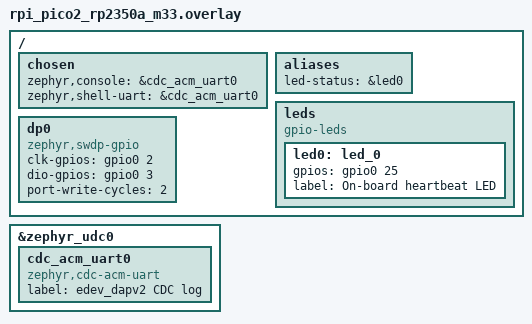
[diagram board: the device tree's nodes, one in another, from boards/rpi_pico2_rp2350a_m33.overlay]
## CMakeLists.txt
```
# SPDX-License-Identifier: Apache-2.0
#
# edev_dapv2 — Zephyr RTOS port.
#
# CMSIS-DAP v2 debug probe firmware for Raspberry Pi Pico 2 (RP2350).
# Ports the working pico-sdk implementation at firmware/projects/edev_dapv2/ to
# Zephyr 4.4.x. The SWD bit-banger is PIO-driven (probe_swd.pio); the rest of
# the stack uses Zephyr USB-Device-Next + subsys/dap.

cmake_minimum_required(VERSION 3.20.0)

find_package(Zephyr REQUIRED HINTS $ENV{ZEPHYR_BASE})
project(edev_dapv2_zephyr LANGUAGES C)

# Pull in the sample USBD helper (sample_usbd_setup_device + Kconfig symbols).
# common.cmake adds sample_usbd_init.c when CONFIG_USB_DEVICE_STACK_NEXT=y and
# wires the include directory.
include(${ZEPHYR_BASE}/samples/subsys/usb/common/common.cmake)

# --------------------------------------------------------------------------
# pioasm — autogenerate probe_swd.pio.h from the .pio source at configure
# time. The pico-sdk vendors pioasm; we use whichever we can find in this
# order: (1) PIOASM env var, (2) system pioasm on PATH, (3) the pico-sdk
# install at ~/.pico-sdk/tools/2.2.0/pioasm/pioasm. If none works, fall back
# to the header that is checked into pio/ so a build is still possible on a
# machine without pioasm.
# --------------------------------------------------------------------------
set(PIO_SRC ${CMAKE_CURRENT_SOURCE_DIR}/pio/probe_swd.pio)
set(PIO_HDR ${CMAKE_CURRENT_BINARY_DIR}/zephyr/include/generated/probe_swd.pio.h)

find_program(PIOASM_EXECUTABLE
    NAMES pioasm
    HINTS
        $ENV{PIOASM}
        $ENV{PICO_SDK_PATH}/tools/pioasm
        $ENV{HOME}/.pico-sdk/tools/2.2.0/pioasm
        $ENV{HOME}/.pico-sdk/tools/2.1.1/pioasm
    DOC "Path to the pioasm executable from pico-sdk"
)

if(PIOASM_EXECUTABLE)
    message(STATUS "pioasm: ${PIOASM_EXECUTABLE} (regenerate ${PIO_HDR} from .pio source)")
    add_custom_command(
        OUTPUT ${PIO_HDR}
        COMMAND ${CMAKE_COMMAND} -E make_directory ${CMAKE_CURRENT_BINARY_DIR}/zephyr/include/generated
        COMMAND ${PIOASM_EXECUTABLE} -o c-sdk ${PIO_SRC} ${PIO_HDR}
        DEPENDS ${PIO_SRC}
        COMMENT "pioasm: ${PIO_SRC} -> probe_swd.pio.h"
        VERBATIM
    )
    add_custom_target(probe_swd_pio_header DEPENDS ${PIO_HDR})
    add_dependencies(app probe_swd_pio_header)
    set(PIO_INCLUDE_DIR ${CMAKE_CURRENT_BINARY_DIR}/zephyr/include/generated)
else()
    message(WARNING
        "pioasm not found — falling back to checked-in pio/probe_swd.pio.h. "
        "Edits to probe_swd.pio will NOT be picked up automatically. "
        "Set PIOASM env var or install pico-sdk to enable regeneration.")
    set(PIO_INCLUDE_DIR ${CMAKE_CURRENT_SOURCE_DIR}/pio)
endif()

target_sources(app PRIVATE
    src/main.c
    src/swclk_keepalive.c
    drivers/dp/swdp_pio_rpi_pico.c
)

# nRF5340 ops — recover/erase/write/read primitives. Off by default;
# enable with CONFIG_EDEV_NRF53_OPS=y. Algorithm reference:
# docs/NRF5340_ALGORITHMS.md.
target_sources(app PRIVATE
    $<$<BOOL:${CONFIG_EDEV_NRF53_OPS}>:src/nrf53/nrf53_dp.c>
    $<$<BOOL:${CONFIG_EDEV_NRF53_OPS}>:src/nrf53/nrf53_ap.c>
    $<$<BOOL:${CONFIG_EDEV_NRF53_OPS}>:src/nrf53/nrf53_ctrl_ap.c>
    $<$<BOOL:${CONFIG_EDEV_NRF53_OPS}>:src/nrf53/nrf53_nvmc.c>
    $<$<BOOL:${CONFIG_EDEV_NRF53_OPS}>:src/nrf53/nrf53_uicr.c>
    $<$<BOOL:${CONFIG_EDEV_NRF53_OPS}>:src/nrf53/nrf53_stubs.c>
    $<$<BOOL:${CONFIG_EDEV_NRF53_OPS}>:src/nrf53/nrf53_recover.c>
    $<$<BOOL:${CONFIG_EDEV_NRF53_OPS}>:src/nrf53/nrf53_read_mem.c>
    $<$<BOOL:${CONFIG_EDEV_NRF53_OPS}>:src/nrf53/nrf53_flash_write.c>
    $<$<BOOL:${CONFIG_EDEV_NRF53_OPS}>:src/nrf53/nrf53_target_info.c>
    $<$<BOOL:${CONFIG_EDEV_NRF53_OPS}>:src/nrf53/nrf53_vendor.c>
)

target_include_directories(app PRIVATE
    src
    src/nrf53
    ${PIO_INCLUDE_DIR}
)
```

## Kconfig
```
# SPDX-License-Identifier: Apache-2.0
#
# edev_dapv2 Zephyr port — application Kconfig.
#
# We reuse the sample USBD helper from samples/subsys/usb/common/. The Zephyr
# upstream policy is that the SAMPLE_USBD_* symbols are sample-scope only — for
# the long-term port we should mint our own EDEV_USBD_* symbols and helper. For
# the M1 scaffold we follow the same shortcut the upstream DAP sample uses.

source "samples/subsys/usb/common/Kconfig.sample_usbd"

rsource "src/nrf53/Kconfig.nrf53"

source "Kconfig.zephyr"
```

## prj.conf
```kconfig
# SPDX-License-Identifier: Apache-2.0
#
# edev_dapv2 Zephyr port — milestone 1 config.
#
# Goal of M1: boot on Pico 2, expose a USB CDC ACM console, blink the on-board
# LED. No DAP wiring yet. Once this builds + flashes + enumerates, layer on the
# DAP subsystem and the swdp_pio_rpi_pico driver.

# Kernel
CONFIG_MAIN_STACK_SIZE=2048
CONFIG_HEAP_MEM_POOL_SIZE=4096

# Console + logging — routed to USB CDC ACM via board overlay
CONFIG_CONSOLE=y
CONFIG_UART_CONSOLE=y
CONFIG_SERIAL=y
CONFIG_UART_INTERRUPT_DRIVEN=y
CONFIG_UART_LINE_CTRL=y
CONFIG_STDOUT_CONSOLE=y

CONFIG_LOG=y
CONFIG_LOG_DEFAULT_LEVEL=3
CONFIG_LOG_MODE_DEFERRED=y

# USB-Device-Next stack
CONFIG_USB_DEVICE_STACK_NEXT=y
CONFIG_USBD_CDC_ACM_LOG_LEVEL_OFF=y
CONFIG_CDC_ACM_SERIAL_INITIALIZE_AT_BOOT=n

# Sample USBD helper (we reuse samples/subsys/usb/common/sample_usbd_init.c)
# VID 0x2E8A is Raspberry Pi Trading's; PID 0x000C is the same value used by
# the pico-sdk edev_dapv2 firmware so host-side allowlists keep working.
CONFIG_SAMPLE_USBD_VID=0x2E8A
CONFIG_SAMPLE_USBD_PID=0x000C
CONFIG_SAMPLE_USBD_MANUFACTURER="Edevkit"
CONFIG_SAMPLE_USBD_PRODUCT="edev_dapv2 (Zephyr)"
CONFIG_SAMPLE_USBD_SELF_POWERED=n
CONFIG_SAMPLE_USBD_REMOTE_WAKEUP=n
CONFIG_SAMPLE_USBD_20_EXTENSION_DESC=y

# Chip-ID serial number — Zephyr's USBD framework calls hwinfo to pull
# RP2350's 64-bit unique ID and exposes it as the SerialNumber string
# descriptor when CONFIG_HWINFO is enabled. Format is a hex string (not the
# "EDV-XXXX-XXXX-XXXX-XXXX" used by pico-sdk firmware — cosmetic only).
CONFIG_HWINFO=y

# BOS chain — needed for MS OS 2.0 Platform Capability descriptor (lets
# Windows auto-bind WINUSB without a .inf file).
CONFIG_USBD_BOS_SUPPORT=y

# Identity strings exposed via DAP_Info command (CMSIS-DAP request 0x00).
CONFIG_CMSIS_DAP_PROBE_VENDOR="Edevkit"
CONFIG_CMSIS_DAP_PROBE_NAME="edev_dapv2 CMSIS-DAP"
CONFIG_CMSIS_DAP_DEVICE_VENDOR="Edevkit"
CONFIG_CMSIS_DAP_DEVICE_NAME="edev_dapv2 (Zephyr)"

# GPIO + drivers
CONFIG_GPIO=y

# DAP subsystem — upstream Zephyr cmsis_dap.c with the SWDP bit-banger as M2
# placeholder. The PIO-backed swdp_pio_rpi_pico driver replaces the bit-banger
# in M3 (DT swap from zephyr,swdp-gpio to zephyr,swdp-pio-rpi-pico).
CONFIG_DAP=y
CONFIG_DAP_BACKEND_USB=y
CONFIG_DAP_LOG_LEVEL_INF=y
CONFIG_DP_DRIVER_LOG_LEVEL_INF=y

# edevkit nRF5340 ops — exposed as CMSIS-DAP vendor commands 0x84..0x8B.
# Algorithm reference: docs/NRF5340_ALGORITHMS.md. Each step in the build
# checklist (§9) wires in one more vendor command; today (step 2) only
# 0x85 NRF53_ERASE is active. Requires the weak-vendor-cmd patch at
# zephyr-patches/0003-cmsis_dap-weak-vendor-cmd-handler.patch.
CONFIG_EDEV_NRF53_OPS=y
CONFIG_EDEV_NRF53_OPS_LOG_LEVEL_INF=y
```

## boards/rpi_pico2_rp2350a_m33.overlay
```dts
/*
 * SPDX-License-Identifier: Apache-2.0
 *
 * edev_dapv2 (Zephyr port) — board overlay for Raspberry Pi Pico 2 (RP2350A,
 * Cortex-M33 cores).
 *
 * Wires:
 *   - USB CDC ACM as the Zephyr console (replaces UART0 console default)
 *   - LED alias to the on-board GPIO25 LED (heartbeat)
 *   - Reserves SWD pins (GPIO2/3) and JTAG pins (GPIO4/5) for later milestones;
 *     no driver is attached yet — driver bindings land with the swdp_pio_rpi
 *     driver in M4.
 */

/ {
	chosen {
		zephyr,console = &cdc_acm_uart0;
		zephyr,shell-uart = &cdc_acm_uart0;
	};

	aliases {
		led-status = &led0;
	};

	leds {
		compatible = "gpio-leds";
		led0: led_0 {
			gpios = <&gpio0 25 GPIO_ACTIVE_HIGH>;
			label = "On-board heartbeat LED";
		};
	};

};

/*
 * SWD Debug Port — production: upstream Zephyr GPIO bit-banger.
 *
 * The PIO-driven driver (raspberrypi,pico-swdp-pio) is preserved in the
 * tree (drivers/dp/) but its DT node is disabled. The GPIO bit-banger
 * proves out the rest of the stack (USB, DAP dispatcher, identity, BLE
 * roadmap, etc.) at the cost of slower SWD speed (~few MHz vs PIO's
 * 25 MHz target). Wire-level FAULT in the PIO driver still needs a
 * logic-analyser session to crack — see UPSTREAM_VALIDATES.md.
 *
 * Pin assignments match probe_pins.h in the pico-sdk project: SWCLK=GP2,
 * SWDIO=GP3 (with internal pull-up — Zephyr's GPIO driver handles RP2350
 * pad isolation correctly via gpio_pin_configure_dt).
 */
/ {
	dp0: dp0 {
		compatible = "zephyr,swdp-gpio";
		status = "okay";
		clk-gpios = <&gpio0 2 GPIO_ACTIVE_HIGH>;
		dio-gpios = <&gpio0 3 GPIO_PULL_UP>;
		port-write-cycles = <2>;
	};
};

&zephyr_udc0 {
	cdc_acm_uart0: cdc_acm_uart0 {
		compatible = "zephyr,cdc-acm-uart";
		label = "edev_dapv2 CDC log";
	};
};
```

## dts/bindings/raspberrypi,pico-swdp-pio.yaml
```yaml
# SPDX-License-Identifier: Apache-2.0
#
# PIO-driven SWDP (Serial Wire Debug Port) for RP2040 / RP2350.
#
# Drop-in replacement for the upstream zephyr,swdp-gpio binding when speed
# matters — the PIO state machine clocks SWD up to 25 MHz (vs ~few-MHz for
# the GPIO bit-banger). The PIO program is the same one the pico-sdk
# implementation at firmware/projects/edev_dapv2/src/pio/probe_swd.pio uses.
#
# Example:
#
#   &pio1 {
#       status = "okay";
#       dp0: dp0 {
#           compatible = "raspberrypi,pico-swdp-pio";
#           status = "okay";
#           clk-gpios = <&gpio0 2 GPIO_ACTIVE_HIGH>;     /* SWCLK */
#           dio-gpios = <&gpio0 3 GPIO_PULL_UP>;         /* SWDIO */
#           reset-gpios = <&gpio0 6 GPIO_ACTIVE_LOW>;    /* nRESET (optional) */
#       };
#   };

description: |
  Raspberry Pi Pico PIO-driven SWDP driver. Implements zephyr/drivers/swdp.h
  for use with subsys/dap. The parent node must be a raspberrypi,pico-pio
  controller; the driver allocates one state machine on it.

compatible: "raspberrypi,pico-swdp-pio"

include: base.yaml

properties:
  clk-gpios:
    type: phandle-array
    required: true
    description: SWCLK pin (always driven by the PIO state machine).

  dio-gpios:
    type: phandle-array
    required: true
    description: SWDIO pin (bidirectional; direction managed by PIO).

  reset-gpios:
    type: phandle-array
    description: |
      Optional nRESET line to the target. Driven open-drain — low pulls the
      target into reset, high (input/Hi-Z) releases it.

  port-write-cycles:
    type: int
    default: 2
    description: |
      Compatibility knob carried over from zephyr,swdp-gpio. Unused by the
      PIO driver because PIO clocks have deterministic phase; kept so
      existing overlays migrate cleanly.
```

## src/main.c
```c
/*
 * SPDX-License-Identifier: Apache-2.0
 *
 * edev_dapv2 (Zephyr port) — M1 entry point.
 *
 * Goal: bring up the board on Zephyr, prove USB CDC console + LED heartbeat
 * work end-to-end before any DAP code lands. Mirrors src/main.c in the pico-sdk
 * project (firmware/projects/edev_dapv2/src/main.c) — same boot order, same
 * banner content, same heartbeat cadence — so a side-by-side comparison while
 * porting is straightforward.
 */

/* Order matters: kernel.h must precede dap_link.h — the latter uses atomic_t
 * without including <zephyr/sys/atomic.h> itself (upstream header omission). */
#include <zephyr/kernel.h>

#include <zephyr/dap/dap_link.h>
#include <zephyr/device.h>
#include <zephyr/drivers/gpio.h>
#include <zephyr/drivers/uart.h>
#include <zephyr/logging/log.h>
#include <zephyr/sys/byteorder.h>
#include <zephyr/usb/bos.h>
#include <zephyr/usb/msos_desc.h>
#include <zephyr/usb/usbd.h>

#include <sample_usbd.h>

#include <pico/bootrom.h>

#if defined(CONFIG_EDEV_NRF53_OPS)
#include "nrf53/nrf53.h"
#endif

LOG_MODULE_REGISTER(edev_dapv2, LOG_LEVEL_INF);

/* MS OS 2.0 BOS — pulled in *after* LOG_MODULE_REGISTER because the static
 * msosv2_to_host_cb in the header uses LOG_INF. The CMSIS-DAP v2 standard
 * device interface GUID it advertises is what makes Windows auto-bind WINUSB
 * (and what makes probe-rs / pyocd / OpenOCD discover the probe). */
#include "msosv2.h"

/* probe-rs gates CMSIS-DAP v2 discovery on bcdDevice >= 0x0220 — see the
 * memory note reference_probe_rs_bcd_device_gate. The Zephyr USBD default
 * uses Zephyr's kernel version; override at runtime to 0x0220 to satisfy the
 * gate without forking the framework. */
#define EDEV_DAPV2_BCD_DEVICE	0x0220

#define LED_NODE	DT_ALIAS(led_status)
#define HEARTBEAT_MS	1000

static const struct gpio_dt_spec led = GPIO_DT_SPEC_GET_OR(LED_NODE, gpios, {0});

/*
 * DAP Link context bound to the SWDP device declared in the board overlay.
 * The compatible string matches the binding in
 * dts/bindings/raspberrypi,pico-swdp-pio.yaml — the PIO-driven backend
 * preserves the 25 MHz SWD speed of the pico-sdk firmware.
 */
DAP_LINK_CONTEXT_DEFINE(edev_dap_ctx, DEVICE_DT_GET_ONE(zephyr_swdp_gpio));

static int setup_usb(void)
{
	struct usbd_context *ctx = sample_usbd_setup_device(NULL);

	if (ctx == NULL) {
		LOG_ERR("USBD setup failed");
		return -ENODEV;
	}

	int ret = usbd_add_descriptor(ctx, &bos_vreq_msosv2);
	if (ret) {
		LOG_ERR("Failed to add MS OS 2.0 BOS: %d", ret);
		return ret;
	}

	ret = usbd_device_set_bcd_device(ctx, EDEV_DAPV2_BCD_DEVICE);
	if (ret) {
		LOG_WRN("Could not set bcdDevice: %d (probe-rs may not list)",
			ret);
	}

	ret = usbd_init(ctx);
	if (ret) {
		LOG_ERR("usbd_init failed: %d", ret);
		return ret;
	}

	ret = usbd_enable(ctx);
	if (ret) {
		LOG_ERR("usbd_enable failed: %d", ret);
		return ret;
	}

	return 0;
}

static void wait_for_dtr(const struct device *console)
{
	uint32_t dtr = 0;

	while (!dtr) {
		uart_line_ctrl_get(console, UART_LINE_CTRL_DTR, &dtr);
		k_sleep(K_MSEC(100));
	}
}

/*
 * 1200-baud-to-BOOTSEL reboot trick.
 *
 * The pico-sdk firmware ports this via TinyUSB's tud_cdc_line_coding_cb. The
 * Zephyr USB-Device-Next CDC ACM driver doesn't expose a line-coding callback,
 * so we poll the console's baud rate every 250 ms; if the host opens at 1200
 * baud (e.g. `stty -f /dev/cu.usbmodem* 1200`) we hand off to the RP2350
 * bootrom to enter UF2 mass-storage mode. This is the same UX the host-side
 * `picotool` / pico-sdk firmware expects.
 */
#define EDEV_REBOOT_MAGIC_BAUD	1200u

static void bootsel_watch_entry(void *a, void *b, void *c)
{
	ARG_UNUSED(a);
	ARG_UNUSED(b);
	ARG_UNUSED(c);

	const struct device *console = DEVICE_DT_GET(DT_CHOSEN(zephyr_console));

	while (!device_is_ready(console)) {
		k_sleep(K_MSEC(100));
	}

	while (1) {
		uint32_t baud = 0;

		uart_line_ctrl_get(console, UART_LINE_CTRL_BAUD_RATE, &baud);
		if (baud == EDEV_REBOOT_MAGIC_BAUD) {
			LOG_WRN("1200-baud — entering BOOTSEL");
			k_sleep(K_MSEC(50));	/* let the log line drain */
			reset_usb_boot(0, 0);
			/* not reached */
		}
		k_sleep(K_MSEC(250));
	}
}

K_THREAD_DEFINE(bootsel_watch, 1024, bootsel_watch_entry, NULL, NULL, NULL,
		K_LOWEST_APPLICATION_THREAD_PRIO, 0, 1000);

static int setup_dap(void)
{
	int ret = dap_link_init(&edev_dap_ctx);

	if (ret) {
		LOG_ERR("dap_link_init failed: %d", ret);
		return ret;
	}

	ret = dap_link_backend_usb_init(&edev_dap_ctx);
	if (ret) {
		LOG_ERR("dap_link_backend_usb_init failed: %d", ret);
		return ret;
	}

	return 0;
}

int main(void)
{
	int ret;

	if (!gpio_is_ready_dt(&led)) {
		LOG_WRN("Status LED not ready");
	} else {
		gpio_pin_configure_dt(&led, GPIO_OUTPUT_INACTIVE);
	}

	ret = setup_dap();
	if (ret) {
		return ret;
	}

#if defined(CONFIG_EDEV_NRF53_OPS)
	/* Bind the SWDP device our nRF5340 ops use. Same device as the DAP
	 * context — we just need our own handle to it because we call the
	 * driver directly (bypassing the DAP dispatcher) when handling our
	 * custom vendor commands (0x84..0x8B). Safe because dispatching is
	 * single-flight: one DAP packet processes at a time. */
	nrf53_status_t ns = nrf53_bind_swdp(DEVICE_DT_GET_ONE(zephyr_swdp_gpio));
	if (ns != NRF53_OK) {
		LOG_WRN("nrf53 ops disabled — SWDP bind failed: %s",
			nrf53_status_str(ns));
	}
#endif /* CONFIG_EDEV_NRF53_OPS */

	ret = setup_usb();
	if (ret) {
		return ret;
	}

	/*
	 * Wait for the host to open the CDC ACM port before printing the boot
	 * banner — otherwise the first ~hundred ms of log lines vanish into a
	 * not-yet-enumerated endpoint. Same idea as the pico-sdk firmware,
	 * which calls tud_cdc_connected() before logging the banner.
	 */
	const struct device *console = DEVICE_DT_GET(DT_CHOSEN(zephyr_console));
	if (device_is_ready(console)) {
		wait_for_dtr(console);
	}

	LOG_INF("edev_dapv2 (Zephyr port) — boot ok");
	LOG_INF("Built: %s %s", __DATE__, __TIME__);

	/* SWCLK keep-alive is staged but LEFT OFF at boot. Live-fire
	 * testing 2026-06-29 showed that an asynchronous SWCLK pulse train
	 * (5 kHz isolated single-cycle pulses) breaks SWD protocol timing
	 * — the chip's frame aligner counts the keep-alive cycles, so
	 * probe-rs's subsequent DPIDR read lands at the wrong bit offset
	 * and returns Protocol Error.
	 *
	 * The right fix is to insert idle cycles INSIDE Zephyr's
	 * drivers/dp/swdp_bitbang.c sw_transfer (the WAIT-ACK retry path
	 * currently exits without clocking; idle cycles between retries
	 * would keep the debug clock alive in-protocol). That's an
	 * upstream patch — tracked in NRF5340_FIRMWARE_GAP.md and the
	 * memory note nrf5340-edev-vs-jlink-firmware-gap-2026-06-29.
	 *
	 * Leaving the timer scaffolding in place so the next session can
	 * call edev_swclk_keepalive_resume() once the in-protocol path is
	 * built. For now it stays gated off via keepalive_active=0. */

	while (1) {
		if (gpio_is_ready_dt(&led)) {
			gpio_pin_toggle_dt(&led);
		}
		k_sleep(K_MSEC(HEARTBEAT_MS));
	}

	return 0;
}
```

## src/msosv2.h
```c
/*
 * Copyright (c) 2016-2019 Intel Corporation
 * Copyright (c) 2023-2024 Nordic Semiconductor ASA
 *
 * SPDX-License-Identifier: Apache-2.0
 *
 * Adapted for edev_dapv2 (Zephyr port). Keeps the standard CMSIS-DAP v2
 * device interface GUID {CDB3B5AD-293B-4663-AA36-1AAE46463776} so probe-rs
 * / pyocd / OpenOCD recognise the probe through their existing CMSIS-DAP v2
 * discovery paths on Windows.
 */

#ifndef EDEV_DAPV2_MSOSV2_H
#define EDEV_DAPV2_MSOSV2_H

#define SAMPLE_MSOS2_VENDOR_CODE	0x02U
/* Windows version (10)*/
#define SAMPLE_MSOS2_OS_VERSION		0x0A000000UL

/* {CDB3B5AD-293B-4663-AA36-1AAE46463776} */
#define CMSIS_DAP_V2_DEVICE_INTERFACE_GUID \
	'{', 0x00, 'C', 0x00, 'D', 0x00, 'B', 0x00, '3', 0x00, 'B', 0x00, \
	'5', 0x00, 'A', 0x00, 'D', 0x00, '-', 0x00, '2', 0x00, '9', 0x00, \
	'3', 0x00, 'B', 0x00, '-', 0x00, '4', 0x00, '6', 0x00, '6', 0x00, \
	'3', 0x00, '-', 0x00, 'A', 0x00, 'A', 0x00, '3', 0x00, '6', 0x00, \
	'-', 0x00, '1', 0x00, 'A', 0x00, 'A', 0x00, 'E', 0x00, '4', 0x00, \
	'6', 0x00, '4', 0x00, '6', 0x00, '3', 0x00, '7', 0x00, '7', 0x00, \
	'6', 0x00, '}', 0x00, 0x00, 0x00, 0x00, 0x00

#define CDC_ACM_DESCRIPTOR_LENGTH 160

struct msosv2_descriptor {
	struct msosv2_descriptor_set_header header;
#if defined(CONFIG_USBD_CDC_ACM_CLASS)
	/*
	 * The composition of this descriptor is specific to the WebUSB example
	 * in its default configuration. If you use it for your application or
	 * change the configuration, you may need to modify this descriptor for
	 * your USB device. The following only covers the case where the CDC
	 * ACM implementation is enabled, and there is only one CDC ACM UART
	 * instance, and the CDC ACM communication interface is the first in
	 * the configuration.
	 */
	struct msosv2_function_subset_header subset_header;
#endif
	struct msosv2_compatible_id compatible_id;
	struct msosv2_guids_property guids_property;
} __packed;

static struct msosv2_descriptor msosv2_desc = {
	.header = {
		.wLength = sizeof(struct msosv2_descriptor_set_header),
		.wDescriptorType = MS_OS_20_SET_HEADER_DESCRIPTOR,
		.dwWindowsVersion = sys_cpu_to_le32(SAMPLE_MSOS2_OS_VERSION),
		.wTotalLength = sizeof(msosv2_desc),
	},
#if defined(CONFIG_USBD_CDC_ACM_CLASS)
	.subset_header = {
		.wLength = sizeof(struct msosv2_function_subset_header),
		.wDescriptorType = MS_OS_20_SUBSET_HEADER_FUNCTION,
		.bFirstInterface = 0,
		.wSubsetLength = CDC_ACM_DESCRIPTOR_LENGTH,
	},
#endif
	.compatible_id = {
		.wLength = sizeof(struct msosv2_compatible_id),
		.wDescriptorType = MS_OS_20_FEATURE_COMPATIBLE_ID,
		.CompatibleID = {'W', 'I', 'N', 'U', 'S', 'B', 0x00, 0x00},
	},
	.guids_property = {
		.wLength = sizeof(struct msosv2_guids_property),
		.wDescriptorType = MS_OS_20_FEATURE_REG_PROPERTY,
		.wPropertyDataType = MS_OS_20_PROPERTY_DATA_REG_MULTI_SZ,
		.wPropertyNameLength = 42,
		.PropertyName = {DEVICE_INTERFACE_GUIDS_PROPERTY_NAME},
		.wPropertyDataLength = 80,
		.bPropertyData = {CMSIS_DAP_V2_DEVICE_INTERFACE_GUID},
	},
};

struct bos_msosv2_descriptor {
	struct usb_bos_platform_descriptor platform;
	struct usb_bos_capability_msos cap;
} __packed;

struct bos_msosv2_descriptor bos_msosv2_desc = {
	/*
	 * Microsoft OS 2.0 Platform Capability Descriptor,
	 * see Microsoft OS 2.0 Descriptors Specification
	 */
	.platform = {
		.bLength = sizeof(struct usb_bos_platform_descriptor)
			 + sizeof(struct usb_bos_capability_msos),
		.bDescriptorType = USB_DESC_DEVICE_CAPABILITY,
		.bDevCapabilityType = USB_BOS_CAPABILITY_PLATFORM,
		.bReserved = 0,
		/* Microsoft OS 2.0 descriptor platform capability UUID
		 * D8DD60DF-4589-4CC7-9CD2-659D9E648A9F
		 */
		.PlatformCapabilityUUID = {
			0xDF, 0x60, 0xDD, 0xD8,
			0x89, 0x45,
			0xC7, 0x4C,
			0x9C, 0xD2,
			0x65, 0x9D, 0x9E, 0x64, 0x8A, 0x9F,
		},
	},
	.cap = {
		.dwWindowsVersion = sys_cpu_to_le32(SAMPLE_MSOS2_OS_VERSION),
		.wMSOSDescriptorSetTotalLength = sys_cpu_to_le16(sizeof(msosv2_desc)),
		.bMS_VendorCode = SAMPLE_MSOS2_VENDOR_CODE,
		.bAltEnumCode = 0x00
	},
};

static int msosv2_to_host_cb(const struct usbd_context *const ctx,
			     const struct usb_setup_packet *const setup,
			     struct net_buf *const buf)
{
	LOG_INF("Vendor callback to host");

	if (setup->bRequest == SAMPLE_MSOS2_VENDOR_CODE &&
	    setup->wIndex == MS_OS_20_DESCRIPTOR_INDEX) {
		LOG_INF("Get MS OS 2.0 Descriptor Set");

		net_buf_add_mem(buf, &msosv2_desc,
				MIN(net_buf_tailroom(buf), sizeof(msosv2_desc)));

		return 0;
	}

	return -ENOTSUP;
}

USBD_DESC_BOS_VREQ_DEFINE(bos_vreq_msosv2, sizeof(bos_msosv2_desc), &bos_msosv2_desc,
			  SAMPLE_MSOS2_VENDOR_CODE, msosv2_to_host_cb, NULL);

#endif /* EDEV_DAPV2_MSOSV2_H */
```

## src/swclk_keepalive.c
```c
/*
 * SPDX-License-Identifier: Apache-2.0
 *
 * SWCLK keep-alive for edev_dapv2 (Zephyr port).
 *
 * Some targets (notably nRF5340 in a deep-wedge state) gate their debug
 * clock domain after a brief idle period on SWCLK. J-Link works around
 * this by continuously toggling SWCLK between debug transactions — it's
 * the "SWCLK keep-alive" or "continuous SWCLK" feature. Without it our
 * probe sees indefinite WAIT-ACK responses on AHB-AP reads, the chip's
 * NVMC ERASEALL never completes, etc.
 *
 * Our pico-sdk firmware had this (PIO0 SM1 driving SWCLK at ~5 kHz, see
 * memory project_swclk_keepalive_pio_2026_06_19) until the v0.2 PIO
 * rebuild dropped it. This Zephyr-side reimplementation uses a CPU-side
 * k_timer firing from the system clock ISR.
 *
 * Why this works without explicit synchronisation with swdp_bitbang:
 *
 *   drivers/dp/swdp_bitbang.c::sw_transfer (and sw_output_sequence and
 *   sw_input_sequence) wrap their inner bit-bang loop in irq_lock(),
 *   which sets PRIMASK=1 on Cortex-M and masks ALL maskable interrupts
 *   including SysTick. Our k_timer expiry runs from SysTick → it's
 *   blocked during the transfer and only fires between transfers, which
 *   is exactly when we want SWCLK kept alive. No race, no extra lock.
 *
 * Tuning: nRF5340's debug clock gate timeout is on the order of
 * milliseconds; 5 kHz (= 200 µs toggle period, 100 µs each level) gives
 * us comfortable margin without burning meaningful CPU.
 */

#include <zephyr/kernel.h>
#include <zephyr/device.h>
#include <zephyr/devicetree.h>
#include <zephyr/drivers/gpio.h>
#include <zephyr/init.h>
#include <zephyr/logging/log.h>

LOG_MODULE_REGISTER(swclk_keepalive, LOG_LEVEL_INF);

/* SWCLK pin lives on the dp0 node's clk-gpios property (board overlay
 * keeps these identical to probe_pins.h: GP2 = SWCLK). Resolve at compile
 * time so we don't pay a DT-lookup cost on every timer tick. */
#define DP0_NODE DT_NODELABEL(dp0)
#if !DT_NODE_HAS_PROP(DP0_NODE, clk_gpios)
#error "dp0 node missing clk-gpios — keep-alive can't resolve SWCLK"
#endif

static const struct gpio_dt_spec swclk =
	GPIO_DT_SPEC_GET(DP0_NODE, clk_gpios);

/* Keep-alive cadence. We send ONE narrow SWCLK pulse per period (below the
 * 50-cycle ADIv5 line-reset threshold, so the chip's DP state machine is
 * unaffected) just often enough to keep the debug clock domain awake.
 *
 * 5 kHz tick → 200 µs between pulses; well under any reasonable debug-clock
 * gate timeout, well under the per-transfer wall-time budget (a 200 kHz SWD
 * transfer is ~250 µs, so during a packet of 8 back-to-back transfers our
 * timer is held off by irq_lock for ~2 ms — we miss ~10 ticks, the timer
 * fires once on resume, no harm done).
 */
#define KEEPALIVE_PERIOD_US 200

static struct k_timer keepalive_timer;
static atomic_t keepalive_active;

/* Expiry runs from the system-clock ISR. Cortex-M PRIMASK (set by
 * irq_lock() in swdp_bitbang during a transfer) blocks all maskable
 * interrupts including SysTick, so we cannot pre-empt a transfer in
 * progress. Between transfers we get a fresh tick window.
 *
 * We deliberately pulse rather than toggle: a toggle leaves SWCLK in an
 * unknown state when the bit-bang takes over (sw_port_on doesn't drive
 * SWCLK level until the first SW_CLOCK_CYCLE). A pulse leaves SWCLK low
 * at the end of every tick, which matches the bit-bang's idle level.
 */
static void keepalive_expiry(struct k_timer *t)
{
	ARG_UNUSED(t);

	if (!atomic_get(&keepalive_active)) {
		return;
	}

	/* Two MMIO stores: SIO.SET then SIO.CLR. ~3 CPU cycles each →
	 * ~40 ns SWCLK high time at 150 MHz. Well above min SWCLK pulse
	 * width on every target SoC we care about (typ. >5 ns). */
	gpio_pin_set_dt(&swclk, 1);
	gpio_pin_set_dt(&swclk, 0);
}

static int swclk_keepalive_init(void)
{
	if (!gpio_is_ready_dt(&swclk)) {
		LOG_ERR("SWCLK GPIO not ready — keep-alive disabled");
		return -ENODEV;
	}

	/* Don't reconfigure direction here — swdp_bitbang's sw_port_on()
	 * owns the SWCLK direction (output when a debug session is active,
	 * disconnected when not). Our timer just toggles via the XOR
	 * register, which is a no-op on an input pin. So keep-alive ticks
	 * are harmless when no session is active and effective when one is.
	 */

	k_timer_init(&keepalive_timer, keepalive_expiry, NULL);

	/* Pin direction is owned by swdp_bitbang's sw_port_on(): SWCLK is
	 * GPIO_DISCONNECTED until DAP_Connect, then GPIO_OUTPUT_INACTIVE.
	 * Our pulse on a DISCONNECTED pin is a no-op (gpio_pin_set_dt
	 * silently returns without driving), so it's safe to arm the
	 * timer unconditionally. When sw_port_on() drives SWCLK output,
	 * the pulses start landing on the wire automatically.
	 *
	 * keepalive_active starts at 0 — the resume hook below flips it on
	 * when the swdp_api consumer signals that a debug session is open.
	 */
	k_timer_start(&keepalive_timer,
		      K_USEC(KEEPALIVE_PERIOD_US),
		      K_USEC(KEEPALIVE_PERIOD_US));

	LOG_INF("SWCLK keep-alive timer armed (%u µs period, gated off)",
		KEEPALIVE_PERIOD_US);
	return 0;
}

/* Public hooks called by the swdp_bitbang sw_port_on/sw_port_off integration.
 * pause() is also called by sw_transfer's caller around batched DAP_Transfer
 * commands; the irq_lock inside sw_transfer takes care of masking the timer
 * during the actual bit-bang, so pause() here is conceptually for the gaps
 * BETWEEN sessions, not BETWEEN transfers. */

void edev_swclk_keepalive_pause(void)
{
	atomic_set(&keepalive_active, 0);
}

void edev_swclk_keepalive_resume(void)
{
	atomic_set(&keepalive_active, 1);
}

SYS_INIT(swclk_keepalive_init, APPLICATION, 90);
```
